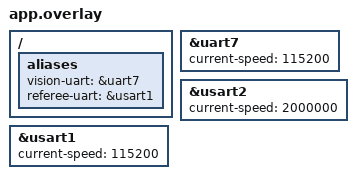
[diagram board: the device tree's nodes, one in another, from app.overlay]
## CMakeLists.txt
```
cmake_minimum_required(VERSION 3.20.0)
find_package(Zephyr REQUIRED HINTS $ENV{ZEPHYR_BASE})
project(command_gimbal)
target_sources(app PRIVATE src/main.cpp)
```

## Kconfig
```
mainmenu "Arbitrated gimbal with staged command sources"

config COMMAND_GIMBAL_REFEREE
    bool "Require actual referee gimbal permission"
    default n
    depends on SKYWALKER_REFEREE

config COMMAND_GIMBAL_VISION_OBSERVE
    bool "Receive vision goals while retaining manual execution"
    default n
    depends on SKYWALKER_VISION_RECEIVER

config COMMAND_GIMBAL_VISION_EXECUTE
    bool "Execute vision inertial goals through the head IMU adapter"
    default n
    depends on SKYWALKER_VISION_RECEIVER && SKYWALKER_IMU_DM_RS485 && SKYWALKER_IMU_RECEIVER

rsource "../common/sample_control.Kconfig"
source "Kconfig.zephyr"
```

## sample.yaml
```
sample:
  name: SkyWalker arbitrated dual-axis command gimbal
  description: MC02 RemoteSource and CommandManager controlling a cross-CAN GM6020 and DM4310 group
common:
  tags: [skywalker, hardware, motor]
  platform_allow: [dm_mc02/stm32h723xx]
  build_only: true
tests:
  sample.skywalker.robotics.command_gimbal: {}
```

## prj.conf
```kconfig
CONFIG_CPP=y
CONFIG_STD_CPP20=y
CONFIG_REQUIRES_FULL_LIBCPP=y
CONFIG_MAIN_STACK_SIZE=6144
CONFIG_HEAP_MEM_POOL_SIZE=0
CONFIG_LOG=y
CONFIG_SERIAL=y
CONFIG_UART_ASYNC_API=y
CONFIG_NOCACHE_MEMORY=y
CONFIG_CAN=y
CONFIG_SKYWALKER_DRIVER_MOTOR=y
CONFIG_SKYWALKER_MOTOR_DJI=y
CONFIG_SKYWALKER_MOTOR_DM=y
CONFIG_SKYWALKER_LIB_CONTROL=y
CONFIG_SKYWALKER_LIB_MOTOR_CONTROL=y
CONFIG_SKYWALKER_LIB_COMMUNICATION=y
CONFIG_SKYWALKER_UART_TRANSPORT=y
CONFIG_SKYWALKER_REMOTE_DR16=y
CONFIG_SKYWALKER_REMOTE_RECEIVER=y
CONFIG_SKYWALKER_LIB_VOFA=y
CONFIG_SKYWALKER_LIB_ROBOTICS=y
CONFIG_SKYWALKER_ROBOTICS_COMMAND=y
CONFIG_SKYWALKER_COMMAND_SERVICE=y
CONFIG_SKYWALKER_COMMAND_PERIOD_MS=10
CONFIG_SKYWALKER_ROBOTICS_GIMBAL=y
CONFIG_SKYWALKER_ROBOTICS_SWERVE=n
CONFIG_SKYWALKER_REFEREE=n
CONFIG_SKYWALKER_INTERBOARD=n
CONFIG_SKYWALKER_IMU=n
CONFIG_SKYWALKER_VISION=n
```

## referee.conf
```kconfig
CONFIG_SKYWALKER_REFEREE=y
CONFIG_COMMAND_GIMBAL_REFEREE=y
```

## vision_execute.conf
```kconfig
CONFIG_MAIN_STACK_SIZE=8192
CONFIG_SKYWALKER_REFEREE=y
CONFIG_COMMAND_GIMBAL_REFEREE=y
CONFIG_SKYWALKER_VISION=y
CONFIG_SKYWALKER_VISION_AB=y
CONFIG_SKYWALKER_VISION_RECEIVER=y
CONFIG_COMMAND_GIMBAL_VISION_EXECUTE=y
CONFIG_SKYWALKER_IMU=y
CONFIG_SKYWALKER_IMU_RECEIVER=y
CONFIG_SKYWALKER_IMU_DM_RS485=y
CONFIG_FPU=y
CONFIG_FPU_SHARING=y
```

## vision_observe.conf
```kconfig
CONFIG_SKYWALKER_REFEREE=y
CONFIG_COMMAND_GIMBAL_REFEREE=y
CONFIG_SKYWALKER_VISION=y
CONFIG_SKYWALKER_VISION_AB=y
CONFIG_SKYWALKER_VISION_RECEIVER=y
CONFIG_COMMAND_GIMBAL_VISION_OBSERVE=y
```

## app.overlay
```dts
/* MC02 supplies can1, can2, remote-uart (UART5), telemetry-uart (USART1)
 * and the console (USART10). Keep transport ownership separate.
 * Hardware model, IDs, calibration and limits live in src/board_config.hpp.
 */
/ {
    aliases {
        vision-uart = &uart7;
        referee-uart = &usart1;
    };
};
/* DMA: SPI2 owns 1/2, UART7 uses 5/7, UART5 uses 6, head RX/TX use 8/11. */
&uart7 {
    current-speed = <115200>;
};
&usart2 {
    current-speed = <2000000>;
};
&usart1 { current-speed = <115200>; };
```

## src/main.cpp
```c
#include <algorithm>
#include <cerrno>
#include <cmath>

#include <core/clock.hpp>
#include <drivers/motor/can_bus.hpp>
#include <lib/vofa/vofa.h>
#include <robotics/command/receiver_sources.hpp>
#include <robotics/execution/snapshot_cache.hpp>
#if defined(CONFIG_COMMAND_GIMBAL_VISION_OBSERVE) || defined(CONFIG_COMMAND_GIMBAL_VISION_EXECUTE)
#include <communication/vision/ab_protocol.hpp>
#endif
#include <zephyr/logging/log.h>
#include <zephyr/sys/atomic.h>

#include "board_config.hpp"
#include "../../common/rc_controls.hpp"
#include "../../common/sample_diagnostics.hpp"

LOG_MODULE_REGISTER(command_gimbal, LOG_LEVEL_INF);
using namespace skywalker;
using namespace skywalker::robotics;

namespace {
atomic_t input_paused = 0, execution_paused = 0, status_paused = 0;
atomic_t emergency_stop = 0, clear_requested = 0;
atomic_t vision_paused = 0, permission_paused = 0, head_paused = 0;
communication::AsyncUart::DmaBuffers remote_dma __nocache;
communication::RemoteReceiver remote(board_config::remote_uart, remote_dma, samples::control::receiverConfig());
RemoteSource remote_source(remote);
// Pausing publication freezes the manager's cached original source stamp; the
// receiver and its DMA worker continue independently.
class PausableRemoteSource final : public ICommandSource {
public:
    SourceRole role() const override {
        return remote_source.role();
    }
    int start() override {
        return remote_source.start();
    }
    int sample(SourceSample &out) override {
        return atomic_get(&input_paused) ? -EAGAIN : remote_source.sample(out);
    }
} pausable_source;
#ifdef CONFIG_COMMAND_GIMBAL_REFEREE
communication::AsyncUart::DmaBuffers referee_dma __nocache;
const device *const referee_uart = DEVICE_DT_GET(DT_ALIAS(referee_uart));
communication::RefereeReceiver referee(referee_uart, referee_dma, 500);
RefereePermissionSource referee_source(referee);
class PausablePermissions final : public IPermissionSource {
public:
    int start() override {
        return referee_source.start();
    }
    int sample(std::uint64_t now_ms, RefereeState &out, SourceDiagnostics &diagnostics) override {
        return atomic_get(&permission_paused) ? -EAGAIN : referee_source.sample(now_ms, out, diagnostics);
    }
} permission_source;
#endif
#if defined(CONFIG_COMMAND_GIMBAL_VISION_OBSERVE) || defined(CONFIG_COMMAND_GIMBAL_VISION_EXECUTE)
communication::AsyncUart::DmaBuffers vision_dma __nocache;
communication::vision::AbProtocol vision_protocol({.command_reference = vehicle::head_reference});
communication::vision::VisionReceiver::Config visionConfig() {
    communication::vision::VisionReceiver::Config c{};
    // AB requires genuine projectile speed/count as well as head measurements.
    // TODO(vision-feedback): connect those measurements before enabling TX;
    // this gimbal-only bench already publishes real head data to setFeedback.
    c.feedback_period_us = 0;
    return c;
}
communication::vision::VisionReceiver vision(DEVICE_DT_GET(DT_ALIAS(vision_uart)), vision_dma, vision_protocol,
                                             visionConfig());
VisionSource vision_source(vision);
class PausableVision final : public ICommandSource {
public:
    SourceRole role() const override {
        return vision_source.role();
    }
    int start() override {
        return vision_source.start();
    }
    int sample(SourceSample &out) override {
        return atomic_get(&vision_paused) ? -EAGAIN : vision_source.sample(out);
    }
} pausable_vision;
#endif
#ifdef CONFIG_COMMAND_GIMBAL_VISION_EXECUTE
communication::AsyncUart::DmaBuffers head_dma __nocache;
imu::DmImuRs485Source head_source(board_config::head_uart, head_dma, board_config::headSensor());
imu::ImuReceiver head(head_source, board_config::head_receiver);
InertialGimbalAdapter inertial_adapter(board_config::inertialPolicy());
#endif
CommandManager commands(board_config::command_policy);
motor::Motor yaw_drive(board_config::yawHardware()), pitch_drive(board_config::pitchHardware());
motor::Group gimbal_group(yaw_drive, pitch_drive);
motor::CanBus yaw_bus(board_config::yaw_can), pitch_bus(board_config::pitch_can);
GimbalExecutor executor(yaw_drive, pitch_drive, gimbal_group, board_config::yawMotorConfig(), board_config::yaw,
                        board_config::pitchMotorConfig(), board_config::pitch, board_config::execution_policy);
struct Observation {
    RunStatus run{};
    double yaw_target = 0, pitch_target = 0;
    core::TimeUs duration_us = 0;
    std::uint32_t cycle_overruns = 0;
    int yaw_commit_error = 0, pitch_commit_error = 0;
#ifdef CONFIG_COMMAND_GIMBAL_VISION_EXECUTE
    InertialGimbalOutput inertial{};
    core::Stamp head_stamp{};
#endif
};
SnapshotCache<Observation> execution_observation;
K_SEM_DEFINE(telemetry_ready, 0, 1);

float age(const MessageStamp &stamp, std::uint64_t now_ms) {
    return stamp.valid && now_ms >= stamp.timestamp_ms ? float(now_ms - stamp.timestamp_ms) : -1.0f;
}

bool permanentSetupError(int error) {
    return error == -EINVAL || error == -ENOTSUP || error == -ENODEV || error == -ENOSPC || error == -EBUSY ||
           error == -EADDRINUSE || error == -ERANGE || error == -EACCES;
}

void telemetryTask(void *, void *, void *) {
    k_sem_take(&telemetry_ready, K_FOREVER);
    static Vofa vofa{};
    const device *const telemetry_uart = DEVICE_DT_GET(DT_ALIAS(telemetry_uart));
    bool telemetry_available = true;
#ifdef CONFIG_COMMAND_GIMBAL_REFEREE
    telemetry_available = telemetry_uart != referee_uart;
#endif
    // USART1 has exactly one owner. With the referee profile, console logs and
    // debugger atomic flags remain available while VOFA RX/TX stays unstarted.
    const int vofa_ret = telemetry_available ? vofa_init(&vofa, telemetry_uart) : -EBUSY;
    LOG_INF("VOFA telemetry start=%d; controls=physical RC", vofa_ret);
    CommandSnapshot frame{};
    Observation observed{};
    std::uint64_t next_log_ms = 0;
    for (;;) {
        (void)commands.snapshot(frame); // Independent, non-consuming reader.
        (void)execution_observation.snapshot(observed);
        const auto now_ms = static_cast<std::uint64_t>(k_uptime_get());
        const auto yaw = yaw_drive.snapshot(), pitch = pitch_drive.snapshot();
        const auto ybus = yaw_bus.status();
        const auto pbus = board_config::pitch_can != board_config::yaw_can ? pitch_bus.status() : ybus;
        const auto &command = frame.decision.command.gimbal;
        const auto feedback = wireFeedback(observed.run, now_ms, board_config::command_timeout_ms);
        const float channels[] = {
            float(frame.observed.remote.stamp.sequence),
            age(frame.observed.remote.stamp, now_ms),
            float(command.stamp.sequence),
            age(command.stamp, now_ms),
            float(unsigned(observed.run.state)),
            float(unsigned(observed.run.reason)),
            float(observed.run.active_count),
            age(observed.run.stamp, now_ms),
            float(observed.run.last_command_sequence),
            yaw.feedback.position_rad,
            pitch.feedback.position_rad,
            float(observed.yaw_target),
            float(observed.pitch_target),
            float(ybus.last_error),
            float(pbus.last_error),
            float(observed.cycle_overruns),
        };
        static_assert(sizeof(channels) / sizeof(channels[0]) <= VOFA_MAX_FLOATS);
        if (vofa_ret == 0)
            (void)vofa_send(&vofa, channels, static_cast<std::uint8_t>(sizeof(channels) / sizeof(channels[0])));
        if (now_ms >= next_log_ms) {
            next_log_ms = now_ms + 1000;
            LOG_INF(
                "source=%u command=%u requested=%d run=%u wait=%u active=%zu waiting=%zu fresh=%d ready=%d error=%d cycle_us=%u overruns=%u commit=%d/%d",
                frame.observed.remote.stamp.sequence, command.stamp.sequence, observed.run.requested,
                unsigned(observed.run.state), unsigned(observed.run.reason), observed.run.active_count,
                observed.run.waiting_count, isFresh(observed.run.stamp, now_ms, board_config::command_timeout_ms),
                feedback.ready, observed.run.error, unsigned(observed.duration_us), observed.cycle_overruns,
                observed.yaw_commit_error, observed.pitch_commit_error);
#if defined(CONFIG_COMMAND_GIMBAL_VISION_OBSERVE) || defined(CONFIG_COMMAND_GIMBAL_VISION_EXECUTE)
            const auto &aim = frame.observed.vision;
            LOG_INF("vision_seq=%llu age_us=%llu control=%d source=%u ref=%u/%u reasons=%x auto=%d", aim.stamp.sequence,
                    aim.stamp.valid && now_ms * 1000 >= aim.stamp.time_us ? now_ms * 1000 - aim.stamp.time_us
                                                                          : UINT64_MAX,
                    aim.value.control_requested, unsigned(command.source), aim.value.reference.frame_id,
                    aim.value.reference.epoch, frame.decision.gimbal_reasons, board_config::command_policy.allow_auto);
#endif
#ifdef CONFIG_COMMAND_GIMBAL_REFEREE
            LOG_INF("referee_online=%d gimbal_allowed=%d permission_age_ms=%d", frame.observed.referee.online,
                    frame.observed.referee.robot.gimbal_output.enabled,
                    int(age(frame.observed.referee.robot.gimbal_output.stamp, now_ms)));
#endif
#ifdef CONFIG_COMMAND_GIMBAL_VISION_EXECUTE
            LOG_INF("head_seq=%llu yaw_output=%d pitch_output=%d stable=%d head_yaw_mrad=%d head_pitch_mrad=%d",
                    observed.head_stamp.sequence, observed.inertial.yaw_output_valid,
                    observed.inertial.pitch_output_valid, observed.inertial.stabilization_valid,
                    int(observed.inertial.head_yaw_rad * 1000), int(observed.inertial.head_pitch_rad * 1000));
#endif
        }
        k_sleep(K_MSEC(50));
    }
}
} // namespace

K_THREAD_DEFINE(telemetry_thread, 4096, telemetryTask, nullptr, nullptr, nullptr, 7, 0, 0);

int main() {
    int ret = commands.registerSource(pausable_source);
#if defined(CONFIG_COMMAND_GIMBAL_VISION_OBSERVE) || defined(CONFIG_COMMAND_GIMBAL_VISION_EXECUTE)
    if (ret == 0)
        ret = commands.registerSource(pausable_vision);
#endif
#ifdef CONFIG_COMMAND_GIMBAL_REFEREE
    if (ret == 0)
        ret = commands.bindPermissions(permission_source);
#endif
#ifdef CONFIG_COMMAND_GIMBAL_VISION_EXECUTE
    if (ret == 0)
        ret = head.start();
#endif
    if (ret == 0)
        ret = commands.start();
    k_sem_give(&telemetry_ready);
    if (ret < 0) {
        LOG_ERR("command service start=%d", ret);
        return ret;
    }
    const bool split_buses = board_config::pitch_can != board_config::yaw_can;
    bool topology_attached = false, yaw_started = false, pitch_started = !split_buses, executor_started = false;
    bool setup_blocked = !board_config::connections_configured;
    int setup_error = board_config::connections_configured ? 0 : -ENODEV;
    std::uint64_t setup_retry_ms = 0;
    if (board_config::connections_configured) {
        ret = split_buses ? yaw_bus.attach(yaw_drive) : yaw_bus.attach(yaw_drive, pitch_drive);
        if (ret == 0 && split_buses)
            ret = pitch_bus.attach(pitch_drive);
        topology_attached = ret == 0;
        setup_error = ret;
        setup_blocked = ret < 0;
        if (setup_blocked)
            LOG_ERR("hardware attach=%d", ret);
    }
    else {
        LOG_WRN("connections_configured=false: calibrate both axes in board_config.hpp before enabling");
    }
    CommandSnapshot frame{};
    Observation observation{};
    core::TimeUs previous_cycle_us = 0;
    samples::control::RcControlAdapter controls({board_config::command_policy.allow_auto});
    samples::control::SampleDiagnostics diagnostics;
    communication::RemoteReceiver::Snapshot operator_cache{};
#ifdef CONFIG_COMMAND_GIMBAL_VISION_EXECUTE
    imu::Snapshot head_cache{};
#endif
    for (;;) {
        (void)remote.snapshot(operator_cache);
        const auto &operator_state = controls.update(operator_cache.remote, k_uptime_get());
        const auto exercise = diagnostics.update(k_uptime_get(), observation.run.state == RunState::Active,
                                                 !operator_state.fresh ||
                                                     operator_state.remote.left_switch == RcSwitch::Down);
        atomic_set(&input_paused, exercise.input_paused);
        atomic_set(&execution_paused, exercise.execution_paused);
        atomic_set(&status_paused, exercise.status_paused);
        atomic_set(&head_paused, exercise.head_paused);
        atomic_set(&vision_paused, exercise.vision_paused);
        atomic_set(&permission_paused, exercise.permission_paused);
        if (operator_state.clear_estop)
            atomic_set(&clear_requested, 1);
        if (atomic_get(&execution_paused) && operator_state.run_allowed && !operator_state.clear_estop &&
            !board_config::emergencyStopRequested() && !atomic_get(&emergency_stop)) {
            // Deliberately freeze the execution producer while command and
            // telemetry workers remain alive. Motor I/O owns expiry/stop.
            k_sleep(K_MSEC(5));
            continue;
        }
        const auto now_us = core::monotonicTimeUs();
        const auto now_ms = now_us / 1000;
        if (topology_attached && !setup_blocked && !executor_started && now_ms >= setup_retry_ms) {
            setup_retry_ms = now_ms + 100;
            int start_error = 0;
            if (!yaw_started) {
                start_error = yaw_bus.start();
                yaw_started = start_error == 0;
            }
            if (start_error == 0 && !pitch_started) {
                start_error = pitch_bus.start();
                pitch_started = start_error == 0;
            }
            if (start_error == 0) {
                start_error = executor.begin();
                executor_started = start_error == 0;
                setup_blocked = start_error < 0; // Axis configuration is a one-shot operation.
            }
            else {
                setup_blocked = permanentSetupError(start_error);
            }
            setup_error = start_error;
            LOG_INF("hardware start/configure=%d blocked=%d", setup_error, setup_blocked);
        }
        if (previous_cycle_us && now_us - previous_cycle_us > board_config::execution_policy.max_cycle_us)
            ++observation.cycle_overruns;
        previous_cycle_us = now_us;
        (void)commands.snapshot(frame);
        GimbalExecutionInputs inputs{};
        inputs.command = frame.decision.command.gimbal;
        if (!operator_state.run_allowed)
            inputs.command.mode = GimbalMode::Disabled;
#ifndef CONFIG_COMMAND_GIMBAL_VISION_EXECUTE
        inputs.command.yaw_rate_rad_s *= board_config::yaw_command_sign;
        inputs.command.pitch_rate_rad_s *= board_config::pitch_command_sign;
#endif
        inputs.source_stamp = sourceStamp(frame, inputs.command.source);
        inputs.transport_ready = executor_started;
        inputs.emergency_stop = atomic_get(&emergency_stop) || board_config::emergencyStopRequested();
        inputs.clear_estop = atomic_set(&clear_requested, 0) || board_config::takeEmergencyResetRequest();
#ifdef CONFIG_COMMAND_GIMBAL_REFEREE
        inputs.require_permission = true;
        inputs.permission = frame.observed.referee.robot.gimbal_output;
#endif
#ifdef CONFIG_COMMAND_GIMBAL_VISION_EXECUTE
        if (!atomic_get(&head_paused))
            head_cache = head.snapshot();
        InertialGimbalInputs inertial{};
        inertial.head = head_cache;
        inertial.yaw = yaw_drive.snapshot();
        inertial.pitch = pitch_drive.snapshot();
        inertial.command = inputs.command;
        inertial.source_stamp = inputs.source_stamp;
        inertial.prerequisites_ready = inputs.transport_ready && vehicle::imu_mounting_confirmed &&
                                       !inputs.emergency_stop && !inputs.clear_estop;
        const bool vision_reference = inputs.command.source != ControlSource::Vision ||
                                      frame.decision.selected_vision.value.reference == head_cache.sample.reference;
        observation.inertial = vision_reference ? inertial_adapter.update(inertial, now_us)
                                                : inertial_adapter.suspend(now_us, WaitReason::Reference, -ESTALE);
        inputs.command = observation.inertial.command;
        inputs.source_stamp = observation.inertial.source_stamp;
        inputs.yaw_output_valid = observation.inertial.yaw_output_valid;
        inputs.pitch_output_valid = observation.inertial.pitch_output_valid;
        observation.head_stamp = head_cache.sample.orientation.stamp;
        communication::vision::Feedback feedback{};
        feedback.mode = frame.decision.operator_mode == OperatorMode::Auto ? communication::vision::Mode::AutoAim
                                                                           : communication::vision::Mode::Idle;
        feedback.reference = head_cache.sample.reference;
        feedback.orientation = head_cache.sample.orientation;
        feedback.gyro_rad_s = head_cache.sample.gyro_rad_s;
        // No shooting sensor exists on this bench; unset measurements remain invalid.
        (void)vision.setFeedback(feedback);
#endif
        observation.run = executor_started
                              ? executor.update(inputs, now_us)
                              : executor.suspend(now_us,
                                                 setup_blocked ? WaitReason::Configuration : WaitReason::Transport,
                                                 setup_error, setup_blocked);
        // Future shared-CAN mechanisms stage here, in this same thread.
        observation.yaw_commit_error = yaw_started ? yaw_bus.commit().error : 0;
        observation.pitch_commit_error = split_buses && pitch_started ? pitch_bus.commit().error : 0;
        observation.yaw_target = executor.yawTargetRad();
        observation.pitch_target = executor.pitchTargetRad();
        observation.duration_us = core::monotonicTimeUs() - now_us;
        if (!atomic_get(&status_paused))
            execution_observation.publish(observation);
        k_sleep(K_MSEC(5));
    }
}
```

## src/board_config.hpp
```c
#pragma once

#include <robotics/vehicle/gimbal_profile.hpp>

#ifdef CONFIG_COMMAND_GIMBAL_VISION_EXECUTE
#include <drivers/imu/dm_imu_rs485.hpp>
#include <drivers/imu/imu_receiver.hpp>
#include <robotics/gimbal/inertial_gimbal.hpp>
#endif

namespace board_config {
namespace calibration = skywalker::robotics::vehicle;
inline constexpr bool connections_configured = calibration::connections_confirmed;
inline constexpr std::uint32_t command_timeout_ms = calibration::gimbal_command_timeout_ms;
inline constexpr std::uint16_t yaw_encoder_zero_ticks = calibration::small_yaw.encoder_zero_ticks;
inline constexpr std::uint16_t yaw_travel_low_ticks = calibration::yaw_low_ticks;
inline constexpr std::uint16_t yaw_travel_high_ticks = calibration::yaw_high_ticks;
inline constexpr float dji_encoder_ticks_per_turn = 8192.0f;
inline constexpr float two_pi = calibration::two_pi;
inline constexpr float yaw_min_angle_rad = calibration::yaw_min_rad;
inline constexpr float yaw_max_angle_rad = calibration::yaw_max_rad;
inline constexpr float yaw_center_rad = calibration::yaw_center_rad;
#if DT_NODE_HAS_STATUS(DT_ALIAS(remote_uart), okay)
inline const device *remote_uart = DEVICE_DT_GET(DT_ALIAS(remote_uart));
#else
inline const device *remote_uart = nullptr;
#endif
inline const device *yaw_can = DEVICE_DT_GET(DT_NODELABEL(can1));
inline const device *pitch_can = DEVICE_DT_GET(DT_NODELABEL(can2));
using calibration::pitchHardware;
using calibration::pitchMotorConfig;
using calibration::yawHardware;
using calibration::yawMotorConfig;
inline constexpr auto yaw = calibration::yawAxisConfig();
inline constexpr auto pitch = calibration::pitchAxisConfig();
inline constexpr float yaw_command_sign = calibration::small_yaw.direction;
inline constexpr float pitch_command_sign = calibration::pitch.direction;

// Connect physical estop/reset inputs here. RC disable remains recoverable.
inline bool emergencyStopRequested() {
    return false;
}
inline bool takeEmergencyResetRequest() {
    return false;
}
// 调参：仅鼠标/发射台架启用的关节目标领先上限（rad）。初值约为
// Yaw 8.6°、Pitch 5.7°，需结合目标-反馈误差及停止拖尾逐轴标定。
// 超出上限的鼠标输入会被丢弃；过小会减弱跟踪/保持，0 表示关闭。
// 不修改上面的通用轴配置，也不将这项关节限幅用于惯性角目标。
inline constexpr float shooter_yaw_max_lead_rad = 0.15f;
inline constexpr float shooter_pitch_max_lead_rad = 0.10f;
inline skywalker::robotics::GimbalAxisConfig shooterYawAxisConfig() {
    auto c = yaw;
    c.max_lead_rad = shooter_yaw_max_lead_rad;
    return c;
}
inline skywalker::robotics::GimbalAxisConfig shooterPitchAxisConfig() {
    auto c = pitch;
    c.max_lead_rad = shooter_pitch_max_lead_rad;
    return c;
}

inline const skywalker::robotics::CommandManager::Config command_policy = [] {
    auto c = calibration::gimbalCommandConfig();
    c.require_referee_for_chassis = IS_ENABLED(CONFIG_COMMAND_GIMBAL_REFEREE);
    c.require_referee_for_gimbal = IS_ENABLED(CONFIG_COMMAND_GIMBAL_REFEREE);
    c.require_referee_for_shooter = IS_ENABLED(CONFIG_COMMAND_GIMBAL_REFEREE);
    c.allow_auto = IS_ENABLED(CONFIG_COMMAND_GIMBAL_VISION_EXECUTE);
    // TODO(reference): AB carries no epoch metadata; negotiate a new reference
    // session with the vision producer after IMU reset before enabling Auto.
    c.expected_vision_reference = calibration::head_reference;
    return c;
}();
inline skywalker::robotics::CommandManager::Config shooterCommandPolicy() {
    auto c = command_policy;
    // 台架专用：左拨杆 Down=Safe、Middle=RC、Up=键鼠；不改其他应用Auto。
    c.mapper.input_profile = skywalker::robotics::RemoteInputProfile::ShooterSelectable;
    c.require_external_run_gate = true;
    c.allow_auto = false;
    c.require_referee_for_chassis = false;
    c.require_referee_for_gimbal = false;
    c.require_referee_for_shooter = false;
    c.enable_shooter = true;
    // 调参：连点间隔严格小于500 ms；达到500 ms无新点击则撤销连发。
    // 长按250 ms是未实机确认的初值，与连点门槛独立。
    c.mouse_gesture.rapid_click_gap_ms = 500;
    c.mouse_gesture.hold_to_auto_ms = 250;
    // 调参：按DR16速度量合同映射，单位为(rad/s)/原始输入单位。
    // 透传量尚未确认是真实鼠标counts；固定DPI/客户端/视场角后标定。
    // 保留旧未饱和区比例，不随下面的机构限速变化，不叠加鼠标滤波。
    c.mapper.mouse_yaw_rate_per_unit = 0.002f;
    c.mapper.mouse_pitch_rate_per_unit = 0.0016f;
    // 调参：独立的操作角速度上限（rad/s）；提高前先确认两轴机械能力。
    c.max_gimbal_yaw_rate_rad_s = 1.0f;
    c.max_gimbal_pitch_rate_rad_s = 0.8f;
    // 统一射频由发射台架用vehicle配置赋值；RC、快速连点与长按共用。
    return c;
}
inline const auto execution_policy = calibration::gimbalExecutionConfig();

#ifdef CONFIG_COMMAND_GIMBAL_VISION_EXECUTE
inline const device *head_uart = DEVICE_DT_GET(DT_ALIAS(rs485_2));
inline constexpr skywalker::imu::ImuReceiver::Config head_receiver{.poll_interval_us = 1000, .priority = 6};
inline skywalker::imu::DmImuRs485Source::Config headSensor() {
    skywalker::imu::DmImuRs485Source::Config c{};
    c.protocol = {1, 20000};
    c.reference = calibration::head_reference;
    c.sensor_to_body = calibration::head_sensor_to_body;
    // TODO(IMU): confirm quaternion direction/scales and vendor quality policy.
    return c;
}
inline skywalker::robotics::InertialGimbalAdapter::Config inertialPolicy() {
    skywalker::robotics::InertialGimbalAdapter::Config c{};
    c.yaw = yaw;
    c.pitch = pitch;
    c.yaw_direction = yaw_command_sign;
    c.pitch_direction = pitch_command_sign;
    c.pitch_locked = false;
    c.allow_unknown_quality = true;
    // TODO(control): validate inertial_gimbal before opening vision execution.
    return c;
}
#endif

} // namespace board_config
```
